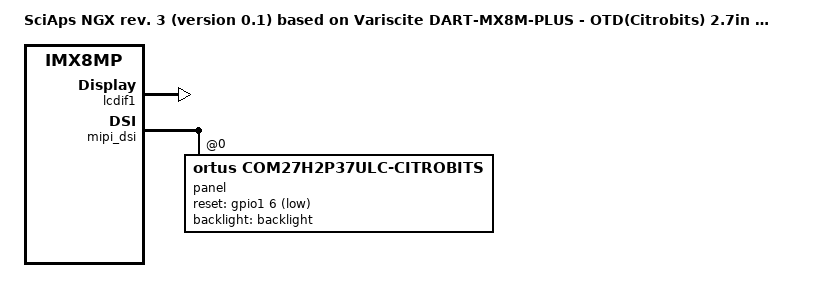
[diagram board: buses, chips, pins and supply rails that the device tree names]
// SPDX-License-Identifier: (GPL-2.0+ OR MIT)
/*
 * Copyright 2019 NXP
 * Copyright 2020-2023 Variscite Ltd.
 * Copyright 2025 SciAps
 */

#include "imx8mp-var-dart-sciaps-ngx.dtsi"

/ {
	model = "SciAps NGX rev. 3 (version 0.1) based on Variscite DART-MX8M-PLUS - OTD(Citrobits) 2.7in Display";
	chosen {
		stdout-path = &uart1;
		//console=ttymxc0,115200 earlycon=ec_imx6q,0x30860000,1/15200 androidboot.console=ttymxc0
		bootargs-append = "androidboot.primary_display=imx-drm androidboot.camera.layout=ov5645-ov7695 androidboot.sciaps.lcd_density=120 moal.mod_para=wifi_mod_para_iw612.conf"; // wifi_mod_para_iw612.conf wifi_mod_para_sd8987.conf
	};
};

&backlight {
    pwms = <&pwm1 0 33000 0>;
};

/* MIPI-DSI */
&lcdif1 {
	swap-line-pattern = "LP_BGR888";
	status = "okay";
};

&mipi_dsi {
	assigned-clock-parents = <&clk IMX8MP_CLK_24M>;
	assigned-clock-rates = <24000000>;
	status = "okay";
	panel@0 {
		compatible = "ortus,com27h2p37ulc-citrobits";
		backlight = <&backlight>;
		reg = <0>;
		pinctrl-0 = <&pinctrl_mipi_dsi_reset>;
		reset-gpios = <&gpio1 6 GPIO_ACTIVE_LOW>;
		dsi-lanes = <1>;
		video-mode = <2>;	/* 0: burst mode
					 * 1: non-burst mode with sync event
					 * 2: non-burst mode with sync pulse
					 */
		status = "okay";
	};
};

#include "imx8mp-android.dtsi"
